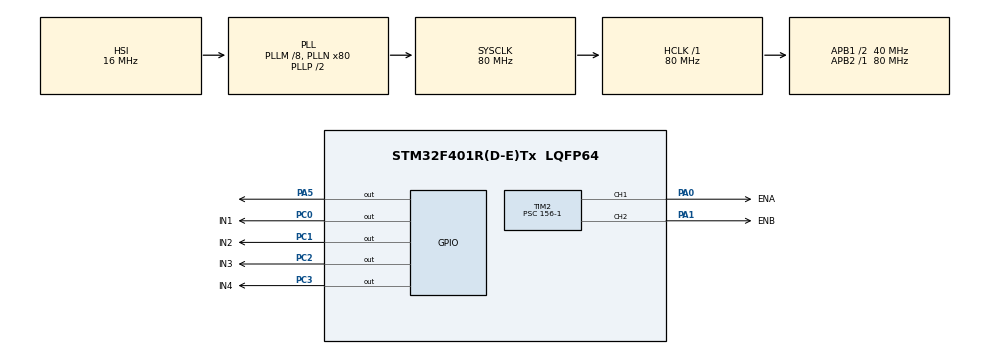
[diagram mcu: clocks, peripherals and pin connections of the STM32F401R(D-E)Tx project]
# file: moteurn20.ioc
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Mcu.Family=STM32F4
Mcu.Name=STM32F401R(D-E)Tx
Mcu.Package=LQFP64
NVIC.PriorityGroup=NVIC_PRIORITYGROUP_0
PA0-WKUP.GPIO_Label=ENA
PA0-WKUP.Signal=S_TIM2_CH1_ETR
PA1.GPIO_Label=ENB
PA1.Signal=S_TIM2_CH2
PA5.Signal=GPIO_Output
PC0.GPIO_Label=IN1
PC0.Signal=GPIO_Output
PC1.GPIO_Label=IN2
PC1.Signal=GPIO_Output
PC2.GPIO_Label=IN3
PC2.Signal=GPIO_Output
PC3.GPIO_Label=IN4
PC3.Signal=GPIO_Output
ProjectManager.HeapSize=0x200
ProjectManager.StackSize=0x400
ProjectManager.TargetToolchain=STM32CubeIDE
RCC.48MHZClocksFreq_Value=22857142.85714286
RCC.AHBFreq_Value=80000000
RCC.APB1CLKDivider=RCC_HCLK_DIV2
RCC.APB1Freq_Value=40000000
RCC.APB1TimFreq_Value=80000000
RCC.APB2Freq_Value=80000000
RCC.APB2TimFreq_Value=80000000
RCC.CortexFreq_Value=80000000
RCC.HCLKFreq_Value=80000000
RCC.HSE_VALUE=8000000
RCC.HSI_VALUE=16000000
RCC.PLLM=8
RCC.PLLN=80
RCC.PLLQ=7
RCC.SYSCLKFreq_VALUE=80000000
RCC.SYSCLKSource=RCC_SYSCLKSOURCE_PLLCLK
RCC.VCOOutputFreq_Value=160000000
SH.S_TIM2_CH1_ETR.0=TIM2_CH1,PWM Generation1 CH1
SH.S_TIM2_CH2.0=TIM2_CH2,PWM Generation2 CH2
TIM2.Channel-PWM\ Generation1\ CH1=TIM_CHANNEL_1
TIM2.Channel-PWM\ Generation2\ CH2=TIM_CHANNEL_2
TIM2.Period=1024-1
TIM2.Prescaler=156-1
board=NUCLEO-F401RE

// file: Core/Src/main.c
/* USER CODE BEGIN Header */
/**
  ******************************************************************************
  * @file           : main.c
  * @brief          : Main program body
  ******************************************************************************
  * @attention
  *
  * Copyright (c) 2024 STMicroelectronics.
  * All rights reserved.
  *
  * This software is licensed under terms that can be found in the LICENSE file
  * in the root directory of this software component.
  * If no LICENSE file comes with this software, it is provided AS-IS.
  *
  ******************************************************************************
  */
/* USER CODE END Header */
#include "main.h"

TIM_HandleTypeDef htim2;

void SystemClock_Config(void);
static void MX_GPIO_Init(void);
static void MX_TIM2_Init(void);
/* USER CODE BEGIN PFP */
/*void forward();
void back();*/
/* USER CODE END PFP */

int main(void)
{

  /* MCU Configuration--------------------------------------------------------*/

  /* Reset of all peripherals, Initializes the Flash interface and the Systick. */
  HAL_Init();

  /* Configure the system clock */
  SystemClock_Config();

  /* Initialize all configured peripherals */
  MX_GPIO_Init();
  MX_TIM2_Init();
  /* USER CODE BEGIN 2 */
  HAL_TIM_PWM_Start(&htim2, TIM_CHANNEL_1);
  HAL_GPIO_WritePin(GPIOC, IN1_Pin, 0);
  HAL_GPIO_WritePin(GPIOC, IN2_Pin, 1);
  TIM2->CCR1=512;
  HAL_TIM_PWM_Start(&htim2, TIM_CHANNEL_2);
  HAL_GPIO_WritePin(GPIOC, IN3_Pin, 0);
  HAL_GPIO_WritePin(GPIOC, IN4_Pin, 1);
  TIM2->CCR2=512;
  /* USER CODE END 2 */

  /* Infinite loop */
  while (1)
  {

    /* USER CODE BEGIN 3 */
	  HAL_GPIO_TogglePin(GPIOA, GPIO_PIN_5);
	  HAL_Delay(50);
  }
  /* USER CODE END 3 */
}

void SystemClock_Config(void)
{
  RCC_OscInitTypeDef RCC_OscInitStruct = {0};
  RCC_ClkInitTypeDef RCC_ClkInitStruct = {0};

  /** Configure the main internal regulator output voltage
  */
  __HAL_RCC_PWR_CLK_ENABLE();
  __HAL_PWR_VOLTAGESCALING_CONFIG(PWR_REGULATOR_VOLTAGE_SCALE2);

  /** Initializes the RCC Oscillators according to the specified parameters
  * in the RCC_OscInitTypeDef structure.
  */
  RCC_OscInitStruct.OscillatorType = RCC_OSCILLATORTYPE_HSI;
  RCC_OscInitStruct.HSIState = RCC_HSI_ON;
  RCC_OscInitStruct.HSICalibrationValue = RCC_HSICALIBRATION_DEFAULT;
  RCC_OscInitStruct.PLL.PLLState = RCC_PLL_ON;
  RCC_OscInitStruct.PLL.PLLSource = RCC_PLLSOURCE_HSI;
  RCC_OscInitStruct.PLL.PLLM = 8;
  RCC_OscInitStruct.PLL.PLLN = 80;
  RCC_OscInitStruct.PLL.PLLP = RCC_PLLP_DIV2;
  RCC_OscInitStruct.PLL.PLLQ = 7;
  if (HAL_RCC_OscConfig(&RCC_OscInitStruct) != HAL_OK)
  {
    Error_Handler();
  }

  /** Initializes the CPU, AHB and APB buses clocks
  */
  RCC_ClkInitStruct.ClockType = RCC_CLOCKTYPE_HCLK|RCC_CLOCKTYPE_SYSCLK
                              |RCC_CLOCKTYPE_PCLK1|RCC_CLOCKTYPE_PCLK2;
  RCC_ClkInitStruct.SYSCLKSource = RCC_SYSCLKSOURCE_PLLCLK;
  RCC_ClkInitStruct.AHBCLKDivider = RCC_SYSCLK_DIV1;
  RCC_ClkInitStruct.APB1CLKDivider = RCC_HCLK_DIV2;
  RCC_ClkInitStruct.APB2CLKDivider = RCC_HCLK_DIV1;

  if (HAL_RCC_ClockConfig(&RCC_ClkInitStruct, FLASH_LATENCY_2) != HAL_OK)
  {
    Error_Handler();
  }
}

static void MX_TIM2_Init(void)
{

  TIM_MasterConfigTypeDef sMasterConfig = {0};
  TIM_OC_InitTypeDef sConfigOC = {0};

  htim2.Instance = TIM2;
  htim2.Init.Prescaler = 156-1;
  htim2.Init.CounterMode = TIM_COUNTERMODE_UP;
  htim2.Init.Period = 1024-1;
  htim2.Init.ClockDivision = TIM_CLOCKDIVISION_DIV1;
  htim2.Init.AutoReloadPreload = TIM_AUTORELOAD_PRELOAD_DISABLE;
  if (HAL_TIM_PWM_Init(&htim2) != HAL_OK)
  {
    Error_Handler();
  }
  sMasterConfig.MasterOutputTrigger = TIM_TRGO_RESET;
  sMasterConfig.MasterSlaveMode = TIM_MASTERSLAVEMODE_DISABLE;
  if (HAL_TIMEx_MasterConfigSynchronization(&htim2, &sMasterConfig) != HAL_OK)
  {
    Error_Handler();
  }
  sConfigOC.OCMode = TIM_OCMODE_PWM1;
  sConfigOC.Pulse = 0;
  sConfigOC.OCPolarity = TIM_OCPOLARITY_HIGH;
  sConfigOC.OCFastMode = TIM_OCFAST_DISABLE;
  if (HAL_TIM_PWM_ConfigChannel(&htim2, &sConfigOC, TIM_CHANNEL_1) != HAL_OK)
  {
    Error_Handler();
  }
  if (HAL_TIM_PWM_ConfigChannel(&htim2, &sConfigOC, TIM_CHANNEL_2) != HAL_OK)
  {
    Error_Handler();
  }
  HAL_TIM_MspPostInit(&htim2);

}

static void MX_GPIO_Init(void)
{
  GPIO_InitTypeDef GPIO_InitStruct = {0};

  /* GPIO Ports Clock Enable */
  __HAL_RCC_GPIOC_CLK_ENABLE();
  __HAL_RCC_GPIOA_CLK_ENABLE();

  /*Configure GPIO pin Output Level */
  HAL_GPIO_WritePin(GPIOC, IN1_Pin|IN2_Pin|IN3_Pin|IN4_Pin, GPIO_PIN_RESET);

  /*Configure GPIO pin Output Level */
  HAL_GPIO_WritePin(GPIOA, GPIO_PIN_5, GPIO_PIN_RESET);

  /*Configure GPIO pins : IN1_Pin IN2_Pin IN3_Pin IN4_Pin */
  GPIO_InitStruct.Pin = IN1_Pin|IN2_Pin|IN3_Pin|IN4_Pin;
  GPIO_InitStruct.Mode = GPIO_MODE_OUTPUT_PP;
  GPIO_InitStruct.Pull = GPIO_NOPULL;
  GPIO_InitStruct.Speed = GPIO_SPEED_FREQ_LOW;
  HAL_GPIO_Init(GPIOC, &GPIO_InitStruct);

  /*Configure GPIO pin : PA5 */
  GPIO_InitStruct.Pin = GPIO_PIN_5;
  GPIO_InitStruct.Mode = GPIO_MODE_OUTPUT_PP;
  GPIO_InitStruct.Pull = GPIO_NOPULL;
  GPIO_InitStruct.Speed = GPIO_SPEED_FREQ_LOW;
  HAL_GPIO_Init(GPIOA, &GPIO_InitStruct);

}

/* USER CODE BEGIN 4 */
/*
void forward(){
 HAL_GPIO_WritePin(GPIOC, IN1_Pin, 0);
 HAL_GPIO_WritePin(GPIOC, IN2_Pin, 1);
 TIM2->CCR1=512;}
void back(){
	 HAL_GPIO_WritePin(GPIOC, IN1_Pin, 1);
	 HAL_GPIO_WritePin(GPIOC, IN2_Pin, 0);
	 TIM2->CCR1=512;
}
void left(){
	 HAL_GPIO_WritePin(GPIOC, IN1_Pin, 1);
	 HAL_GPIO_WritePin(GPIOC, IN2_Pin, 0);
	 TIM2->CCR1=512;
	 HAL_GPIO_WritePin(GPIOC, IN3_Pin, 0);
	 HAL_GPIO_WritePin(GPIOC, IN4_Pin, 1);
	 TIM2->CCR2=200;
}*/
/* USER CODE END 4 */

void Error_Handler(void)
{
  __disable_irq();
  while (1)
  {
  }
}
